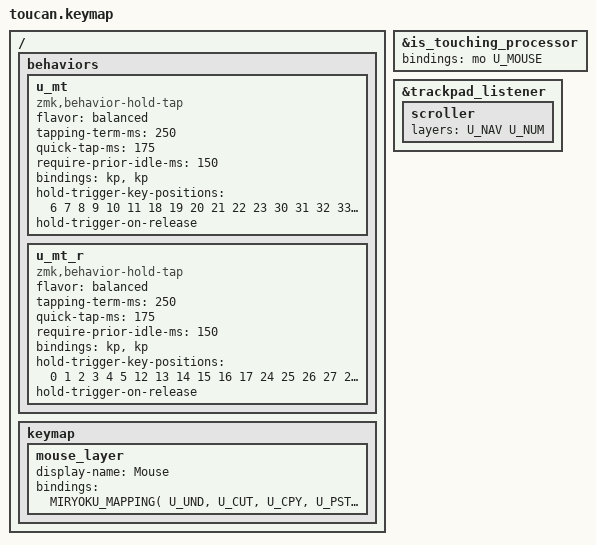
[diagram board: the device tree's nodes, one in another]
// Miryoku for the beekeeb Toucan2 (42-key split).
// Engine: https://github.com/manna-harbour/miryoku_zmk (vendored under config/miryoku/)
// Options: QWERTY alphas, inverted-T navigation, flipped layers --
// see miryoku/custom_config.h. Board mapping: miryoku/mapping/42/toucan2.h
//
// This overrides the stock shield keymap at
// boards/shields/toucan/toucan.keymap (kept as upstream ships it).
// After flashing a changed layer list, flash settings_reset (or use ZMK
// Studio "Restore Stock Settings") so stored Studio edits don't shadow it.

#include "miryoku/custom_config.h"
#include "miryoku/mapping/42/toucan2.h"
#include "miryoku/miryoku.dtsi"

// ---------------------------------------------------------------------------
// Mouse layer (keymap index 9, right after the 9 Miryoku layers).
//
// This is the Toucan2's touch-activated mouse layer, replacing the stock
// firmware's MOU layer. Stock MOU was all-transparent (inheriting Base)
// with only mouse buttons on the thumbs; here Miryoku's Button layer
// content is merged in -- mouse buttons on the thumbs, clipboard
// (Undo/Cut/Copy/Paste/Redo) on the top and bottom rows, mods on the home
// row (right-hand versions on the right, as customized). Miryoku's
// standalone Button layer is removed (see miryoku/custom_config.h); this
// layer carries its content instead.
//
// Reached by touching the trackpad (is_touching_processor below), or on
// the Extra layer by holding Z or / -- all resolve to U_MOUSE via
// miryoku/custom_config.h.
// (On the Base layer the thumb TAB key holds for Sym; the touch Mouse
// layer itself is the trackpad's job.)
// ---------------------------------------------------------------------------
// ---------------------------------------------------------------------------
// Home-row mod behaviors (override Miryoku's u_mt).
//
// Adopted from https://github.com/LifeBringer/zmk-keyboard-toucan with
// tapping-term-ms reduced to 250 (theirs is 280):
//   - flavor "balanced": hold fires only on opposite-hand keypress, so
//     rolling two keys on the same hand won't misfire a mod.
//   - quick-tap-ms 175: rapid re-taps still register as taps.
//   - require-prior-idle-ms 150: the mod only engages after 150ms of
//     no keypresses, guarding against accidental holds while typing fast.
//   - hold-trigger-on-release: the hold is decided when the key is
//     released, not when another key is pressed.
//
// Two behaviors because the hold-trigger positions are hand-specific:
//   - u_mt   (left-hand mods): hold triggers on right-hand keys + thumbs.
//   - u_mt_r (right-hand mods): hold triggers on left-hand keys + thumbs.
// Toucan2 key positions (12 cols x 4 rows): left = 0-5, 12-17, 24-29,
// 36-38; right = 6-11, 18-23, 30-35, 39-41; thumbs = 36-41.
// Use U_MT for left mods, U_MT_R (defined in miryoku/custom_config.h)
// for right mods.
// ---------------------------------------------------------------------------
/ {
    behaviors {
        u_mt: u_mt {
            compatible = "zmk,behavior-hold-tap";
            #binding-cells = <2>;
            flavor = "balanced";
            tapping-term-ms = <250>;
            quick-tap-ms = <175>;
            require-prior-idle-ms = <150>;
            bindings = <&kp>, <&kp>;
            hold-trigger-key-positions = <6 7 8 9 10 11 18 19 20 21 22 23 30 31 32 33 34 35 36 37 38 39 40 41>;
            hold-trigger-on-release;
        };
        u_mt_r: u_mt_r {
            compatible = "zmk,behavior-hold-tap";
            #binding-cells = <2>;
            flavor = "balanced";
            tapping-term-ms = <250>;
            quick-tap-ms = <175>;
            require-prior-idle-ms = <150>;
            bindings = <&kp>, <&kp>;
            hold-trigger-key-positions = <0 1 2 3 4 5 12 13 14 15 16 17 24 25 26 27 28 29 36 37 38 39 40 41>;
            hold-trigger-on-release;
        };
    };

    keymap {
        mouse_layer {
            display-name = "Mouse";
            bindings = <
                MIRYOKU_MAPPING(
                    U_UND,     U_CUT,     U_CPY,     U_PST,     U_RDO,        U_RDO,     U_PST,     U_CPY,     U_CUT,     U_UND,
                    &kp LGUI,  &kp LALT,  &kp LCTRL, &kp LSHFT, U_NU,         U_NU,      &kp RSHFT, &kp RCTRL, &kp RALT,  &kp RGUI,
                    U_UND,     U_CUT,     U_CPY,     U_PST,     U_RDO,        U_RDO,     U_PST,     U_CPY,     U_CUT,     U_UND,
                    U_NP,      U_NP,      U_BTN3,    U_BTN1,    U_BTN2,       U_BTN2,    U_BTN1,    U_BTN3,    U_NP,      U_NP,
                    &none,     &none,     &none,                &none,     &none,     &none
                )
            >;
        };
    };
};

// The Toucan2 shield holds a layer while the trackpad is touched
// (boards/shields/toucan/toucan.dtsi: is_touching_processor).
// Stock holds its MOU layer; here it holds the Mouse layer defined above
// (U_MOUSE = 9): mouse buttons + clipboard + mods while the trackpad moves
// the cursor natively under your finger.
&is_touching_processor {
    bindings = <&mo U_MOUSE>;
};

// The shield turns one-finger trackpad motion into scrolling while layers
// 1 or 2 are active (stock NAV / SYM). Under the Miryoku numbering those
// are Extra and Tap -- alpha layers -- so retarget the scroller at Nav
// (hold BSPC) and Num (hold SPACE).
&trackpad_listener {
    scroller {
        layers = <U_NAV U_NUM>;
    };
};

// The engine's SYM layer references the u_to_U_MOUSE double-tap-guard
// behavior, which the custom 9-layer list in miryoku/custom_config.h
// (no Miryoku Mouse layer) doesn't generate. Provide it, targeting the
// touch Mouse layer, reusing the engine's own macro.
MIRYOKU_DOUBLE_TAP_GUARD(u_to_U_MOUSE, &to U_MOUSE)
